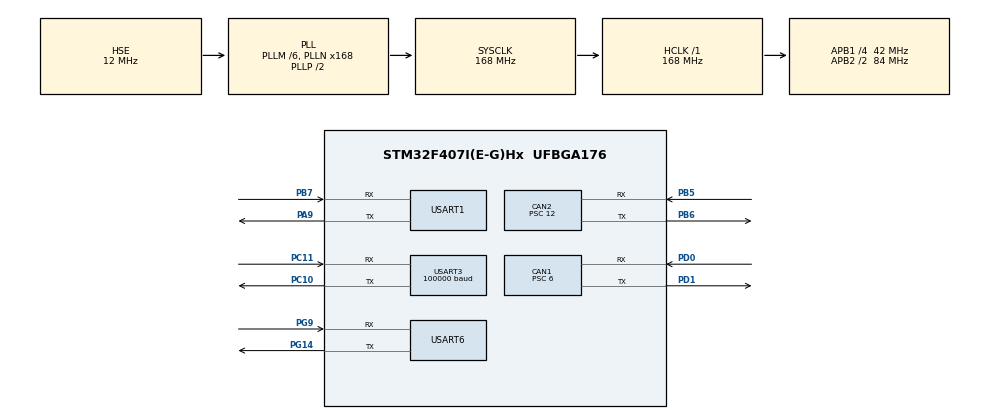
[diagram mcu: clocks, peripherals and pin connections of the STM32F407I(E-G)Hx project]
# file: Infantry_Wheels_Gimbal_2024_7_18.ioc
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CAN1.BS1=CAN_BS1_4TQ
CAN1.BS2=CAN_BS2_2TQ
CAN1.CalculateBaudRate=1000000
CAN1.CalculateTimeBit=1000
CAN1.CalculateTimeQuantum=142.85714285714286
CAN1.Prescaler=6
CAN2.BS1=CAN_BS1_4TQ
CAN2.BS2=CAN_BS2_2TQ
CAN2.CalculateBaudRate=500000
CAN2.CalculateTimeBit=2000
CAN2.CalculateTimeQuantum=285.7142857142857
CAN2.Prescaler=12
Dma.Request0=USART1_RX
Dma.Request1=USART1_TX
Dma.Request2=USART6_RX
Dma.Request3=USART6_TX
Dma.USART1_RX.0.Direction=DMA_PERIPH_TO_MEMORY
Dma.USART1_RX.0.FIFOMode=DMA_FIFOMODE_DISABLE
Dma.USART1_RX.0.Instance=DMA2_Stream2
Dma.USART1_RX.0.MemDataAlignment=DMA_MDATAALIGN_BYTE
Dma.USART1_RX.0.MemInc=DMA_MINC_ENABLE
Dma.USART1_RX.0.Mode=DMA_NORMAL
Dma.USART1_RX.0.PeriphDataAlignment=DMA_PDATAALIGN_BYTE
Dma.USART1_RX.0.PeriphInc=DMA_PINC_DISABLE
Dma.USART1_RX.0.Priority=DMA_PRIORITY_LOW
Dma.USART1_TX.1.Direction=DMA_MEMORY_TO_PERIPH
Dma.USART1_TX.1.FIFOMode=DMA_FIFOMODE_DISABLE
Dma.USART1_TX.1.Instance=DMA2_Stream7
Dma.USART1_TX.1.MemDataAlignment=DMA_MDATAALIGN_BYTE
Dma.USART1_TX.1.MemInc=DMA_MINC_ENABLE
Dma.USART1_TX.1.Mode=DMA_NORMAL
Dma.USART1_TX.1.PeriphDataAlignment=DMA_PDATAALIGN_BYTE
Dma.USART1_TX.1.PeriphInc=DMA_PINC_DISABLE
Dma.USART1_TX.1.Priority=DMA_PRIORITY_LOW
Dma.USART6_RX.2.Direction=DMA_PERIPH_TO_MEMORY
Dma.USART6_RX.2.FIFOMode=DMA_FIFOMODE_DISABLE
Dma.USART6_RX.2.Instance=DMA2_Stream1
Dma.USART6_RX.2.MemDataAlignment=DMA_MDATAALIGN_BYTE
Dma.USART6_RX.2.MemInc=DMA_MINC_ENABLE
Dma.USART6_RX.2.Mode=DMA_NORMAL
Dma.USART6_RX.2.PeriphDataAlignment=DMA_PDATAALIGN_BYTE
Dma.USART6_RX.2.PeriphInc=DMA_PINC_DISABLE
Dma.USART6_RX.2.Priority=DMA_PRIORITY_LOW
Dma.USART6_TX.3.Direction=DMA_MEMORY_TO_PERIPH
Dma.USART6_TX.3.FIFOMode=DMA_FIFOMODE_DISABLE
Dma.USART6_TX.3.Instance=DMA2_Stream6
Dma.USART6_TX.3.MemDataAlignment=DMA_MDATAALIGN_BYTE
Dma.USART6_TX.3.MemInc=DMA_MINC_ENABLE
Dma.USART6_TX.3.Mode=DMA_NORMAL
Dma.USART6_TX.3.PeriphDataAlignment=DMA_PDATAALIGN_BYTE
Dma.USART6_TX.3.PeriphInc=DMA_PINC_DISABLE
Dma.USART6_TX.3.Priority=DMA_PRIORITY_LOW
Mcu.Family=STM32F4
Mcu.Name=STM32F407I(E-G)Hx
Mcu.Package=UFBGA176
NVIC.CAN1_RX0_IRQn=true\:0\:0\:false\:false\:true\:true\:true\:true
NVIC.CAN1_RX1_IRQn=true\:0\:0\:false\:false\:true\:true\:true\:true
NVIC.CAN2_RX0_IRQn=true\:0\:0\:false\:false\:true\:true\:true\:true
NVIC.CAN2_RX1_IRQn=true\:0\:0\:false\:false\:true\:true\:true\:true
NVIC.DMA2_Stream1_IRQn=true\:0\:0\:false\:false\:true\:false\:true\:true
NVIC.DMA2_Stream2_IRQn=true\:0\:0\:false\:false\:true\:false\:true\:true
NVIC.DMA2_Stream6_IRQn=true\:0\:0\:false\:false\:true\:false\:true\:true
NVIC.DMA2_Stream7_IRQn=true\:0\:0\:false\:false\:true\:false\:true\:true
NVIC.PriorityGroup=NVIC_PRIORITYGROUP_4
NVIC.TIM5_IRQn=true\:0\:0\:false\:false\:true\:true\:true\:true
NVIC.TIM6_DAC_IRQn=true\:0\:0\:false\:false\:true\:true\:true\:true
NVIC.USART1_IRQn=true\:0\:0\:false\:false\:true\:true\:true\:true
NVIC.USART3_IRQn=true\:0\:0\:false\:false\:true\:true\:true\:true
NVIC.USART6_IRQn=true\:0\:0\:false\:false\:true\:true\:true\:true
PA13.Mode=Serial_Wire
PA13.Signal=SYS_JTMS-SWDIO
PA14.Mode=Serial_Wire
PA14.Signal=SYS_JTCK-SWCLK
PA9.Mode=Asynchronous
PA9.Signal=USART1_TX
PB5.Mode=CAN_Activate
PB5.Signal=CAN2_RX
PB6.Mode=CAN_Activate
PB6.Signal=CAN2_TX
PB7.Mode=Asynchronous
PB7.Signal=USART1_RX
PC10.Mode=Asynchronous
PC10.Signal=USART3_TX
PC11.Mode=Asynchronous
PC11.Signal=USART3_RX
PD0.Mode=CAN_Activate
PD0.Signal=CAN1_RX
PD1.Mode=CAN_Activate
PD1.Signal=CAN1_TX
PG14.Mode=Asynchronous
PG14.Signal=USART6_TX
PG9.Mode=Asynchronous
PG9.Signal=USART6_RX
PH0-OSC_IN.Mode=HSE-External-Oscillator
PH0-OSC_IN.Signal=RCC_OSC_IN
PH1-OSC_OUT.Mode=HSE-External-Oscillator
PH1-OSC_OUT.Signal=RCC_OSC_OUT
ProjectManager.HeapSize=0x200
ProjectManager.StackSize=0x400
ProjectManager.TargetToolchain=MDK-ARM V5.32
RCC.48MHZClocksFreq_Value=84000000
RCC.AHBFreq_Value=168000000
RCC.APB1CLKDivider=RCC_HCLK_DIV4
RCC.APB1Freq_Value=42000000
RCC.APB1TimFreq_Value=84000000
RCC.APB2CLKDivider=RCC_HCLK_DIV2
RCC.APB2Freq_Value=84000000
RCC.APB2TimFreq_Value=168000000
RCC.CortexFreq_Value=168000000
RCC.HCLKFreq_Value=168000000
RCC.HSE_VALUE=12000000
RCC.HSI_VALUE=16000000
RCC.LSE_VALUE=32768
RCC.PLLM=6
RCC.PLLN=168
RCC.PLLSourceVirtual=RCC_PLLSOURCE_HSE
RCC.SYSCLKFreq_VALUE=168000000
RCC.SYSCLKSource=RCC_SYSCLKSOURCE_PLLCLK
RCC.VCOOutputFreq_Value=336000000
TIM5.AutoReloadPreload=TIM_AUTORELOAD_PRELOAD_ENABLE
TIM5.Period=1000-1
TIM5.Prescaler=84-1
TIM6.AutoReloadPreload=TIM_AUTORELOAD_PRELOAD_ENABLE
TIM6.Period=1000-1
TIM6.Prescaler=84-1
USART1.VirtualMode=VM_ASYNC
USART3.BaudRate=100000
USART3.Parity=PARITY_EVEN
USART3.VirtualMode=VM_ASYNC
USART3.WordLength=WORDLENGTH_9B
USART6.VirtualMode=VM_ASYNC
VP_TIM5_VS_ClockSourceINT.Mode=Internal
VP_TIM6_VS_ClockSourceINT.Mode=Enable_Timer
board=custom

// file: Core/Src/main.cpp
/* USER CODE BEGIN Header */
/**
  ******************************************************************************
  * @file           : main.c
  * @brief          : Main program body
  ******************************************************************************
  * @attention
  *
  * Copyright (c) 2024 STMicroelectronics.
  * All rights reserved.
  *
  * This software is licensed under terms that can be found in the LICENSE file
  * in the root directory of this software component.
  * If no LICENSE file comes with this software, it is provided AS-IS.
  *
  ******************************************************************************
  */
/* USER CODE END Header */
#include "main.h"
#include "can.h"
#include "dma.h"
#include "tim.h"
#include "usart.h"
#include "gpio.h"

/* USER CODE BEGIN Includes */
#include "Total_stack.h"
/* USER CODE END Includes */

void SystemClock_Config(void);

int main(void)
{

  /* MCU Configuration--------------------------------------------------------*/

  /* Reset of all peripherals, Initializes the Flash interface and the Systick. */
  HAL_Init();

  /* Configure the system clock */
  SystemClock_Config();

  /* Initialize all configured peripherals */
  MX_GPIO_Init();
  MX_DMA_Init();
  MX_CAN1_Init();
  MX_CAN2_Init();
  MX_USART1_UART_Init();
  MX_USART3_UART_Init();
  MX_USART6_UART_Init();
  MX_TIM5_Init();
  MX_TIM6_Init();
  /* USER CODE BEGIN 2 */
	Total_tasks_Init();//?????????????
	HAL_TIM_Base_Start_IT(&htim6);//?????????
	HAL_TIM_Base_Start_IT(&htim5);//????
  /* USER CODE END 2 */

  /* Infinite loop */
  while (1)
  {

    /* USER CODE BEGIN 3 */
		Total_tasks_Run();
  }
  /* USER CODE END 3 */
}

void SystemClock_Config(void)
{
  RCC_OscInitTypeDef RCC_OscInitStruct = {0};
  RCC_ClkInitTypeDef RCC_ClkInitStruct = {0};

  /** Configure the main internal regulator output voltage
  */
  __HAL_RCC_PWR_CLK_ENABLE();
  __HAL_PWR_VOLTAGESCALING_CONFIG(PWR_REGULATOR_VOLTAGE_SCALE1);

  /** Initializes the RCC Oscillators according to the specified parameters
  * in the RCC_OscInitTypeDef structure.
  */
  RCC_OscInitStruct.OscillatorType = RCC_OSCILLATORTYPE_HSE;
  RCC_OscInitStruct.HSEState = RCC_HSE_ON;
  RCC_OscInitStruct.PLL.PLLState = RCC_PLL_ON;
  RCC_OscInitStruct.PLL.PLLSource = RCC_PLLSOURCE_HSE;
  RCC_OscInitStruct.PLL.PLLM = 6;
  RCC_OscInitStruct.PLL.PLLN = 168;
  RCC_OscInitStruct.PLL.PLLP = RCC_PLLP_DIV2;
  RCC_OscInitStruct.PLL.PLLQ = 4;
  if (HAL_RCC_OscConfig(&RCC_OscInitStruct) != HAL_OK)
  {
    Error_Handler();
  }

  /** Initializes the CPU, AHB and APB buses clocks
  */
  RCC_ClkInitStruct.ClockType = RCC_CLOCKTYPE_HCLK|RCC_CLOCKTYPE_SYSCLK
                              |RCC_CLOCKTYPE_PCLK1|RCC_CLOCKTYPE_PCLK2;
  RCC_ClkInitStruct.SYSCLKSource = RCC_SYSCLKSOURCE_PLLCLK;
  RCC_ClkInitStruct.AHBCLKDivider = RCC_SYSCLK_DIV1;
  RCC_ClkInitStruct.APB1CLKDivider = RCC_HCLK_DIV4;
  RCC_ClkInitStruct.APB2CLKDivider = RCC_HCLK_DIV2;

  if (HAL_RCC_ClockConfig(&RCC_ClkInitStruct, FLASH_LATENCY_5) != HAL_OK)
  {
    Error_Handler();
  }
}

static void MX_CAN1_Init(void)
{

  hcan1.Instance = CAN1;
  hcan1.Init.Prescaler = 6;
  hcan1.Init.Mode = CAN_MODE_NORMAL;
  hcan1.Init.SyncJumpWidth = CAN_SJW_1TQ;
  hcan1.Init.TimeSeg1 = CAN_BS1_4TQ;
  hcan1.Init.TimeSeg2 = CAN_BS2_2TQ;
  hcan1.Init.TimeTriggeredMode = DISABLE;
  hcan1.Init.AutoBusOff = DISABLE;
  hcan1.Init.AutoWakeUp = DISABLE;
  hcan1.Init.AutoRetransmission = DISABLE;
  hcan1.Init.ReceiveFifoLocked = DISABLE;
  hcan1.Init.TransmitFifoPriority = DISABLE;
  if (HAL_CAN_Init(&hcan1) != HAL_OK)
  {
    Error_Handler();
  }

}

static void MX_CAN2_Init(void)
{

  hcan2.Instance = CAN2;
  hcan2.Init.Prescaler = 12;
  hcan2.Init.Mode = CAN_MODE_NORMAL;
  hcan2.Init.SyncJumpWidth = CAN_SJW_1TQ;
  hcan2.Init.TimeSeg1 = CAN_BS1_4TQ;
  hcan2.Init.TimeSeg2 = CAN_BS2_2TQ;
  hcan2.Init.TimeTriggeredMode = DISABLE;
  hcan2.Init.AutoBusOff = DISABLE;
  hcan2.Init.AutoWakeUp = DISABLE;
  hcan2.Init.AutoRetransmission = DISABLE;
  hcan2.Init.ReceiveFifoLocked = DISABLE;
  hcan2.Init.TransmitFifoPriority = DISABLE;
  if (HAL_CAN_Init(&hcan2) != HAL_OK)
  {
    Error_Handler();
  }

}

static void MX_TIM5_Init(void)
{

  TIM_ClockConfigTypeDef sClockSourceConfig = {0};
  TIM_MasterConfigTypeDef sMasterConfig = {0};

  htim5.Instance = TIM5;
  htim5.Init.Prescaler = 84-1;
  htim5.Init.CounterMode = TIM_COUNTERMODE_UP;
  htim5.Init.Period = 1000-1;
  htim5.Init.ClockDivision = TIM_CLOCKDIVISION_DIV1;
  htim5.Init.AutoReloadPreload = TIM_AUTORELOAD_PRELOAD_ENABLE;
  if (HAL_TIM_Base_Init(&htim5) != HAL_OK)
  {
    Error_Handler();
  }
  sClockSourceConfig.ClockSource = TIM_CLOCKSOURCE_INTERNAL;
  if (HAL_TIM_ConfigClockSource(&htim5, &sClockSourceConfig) != HAL_OK)
  {
    Error_Handler();
  }
  sMasterConfig.MasterOutputTrigger = TIM_TRGO_RESET;
  sMasterConfig.MasterSlaveMode = TIM_MASTERSLAVEMODE_DISABLE;
  if (HAL_TIMEx_MasterConfigSynchronization(&htim5, &sMasterConfig) != HAL_OK)
  {
    Error_Handler();
  }

}

static void MX_TIM6_Init(void)
{

  TIM_MasterConfigTypeDef sMasterConfig = {0};

  htim6.Instance = TIM6;
  htim6.Init.Prescaler = 84-1;
  htim6.Init.CounterMode = TIM_COUNTERMODE_UP;
  htim6.Init.Period = 1000-1;
  htim6.Init.AutoReloadPreload = TIM_AUTORELOAD_PRELOAD_ENABLE;
  if (HAL_TIM_Base_Init(&htim6) != HAL_OK)
  {
    Error_Handler();
  }
  sMasterConfig.MasterOutputTrigger = TIM_TRGO_RESET;
  sMasterConfig.MasterSlaveMode = TIM_MASTERSLAVEMODE_DISABLE;
  if (HAL_TIMEx_MasterConfigSynchronization(&htim6, &sMasterConfig) != HAL_OK)
  {
    Error_Handler();
  }

}

static void MX_USART1_UART_Init(void)
{

  huart1.Instance = USART1;
  huart1.Init.BaudRate = 115200;
  huart1.Init.WordLength = UART_WORDLENGTH_8B;
  huart1.Init.StopBits = UART_STOPBITS_1;
  huart1.Init.Parity = UART_PARITY_NONE;
  huart1.Init.Mode = UART_MODE_TX_RX;
  huart1.Init.HwFlowCtl = UART_HWCONTROL_NONE;
  huart1.Init.OverSampling = UART_OVERSAMPLING_16;
  if (HAL_UART_Init(&huart1) != HAL_OK)
  {
    Error_Handler();
  }

}

static void MX_USART3_UART_Init(void)
{

  huart3.Instance = USART3;
  huart3.Init.BaudRate = 100000;
  huart3.Init.WordLength = UART_WORDLENGTH_9B;
  huart3.Init.StopBits = UART_STOPBITS_1;
  huart3.Init.Parity = UART_PARITY_EVEN;
  huart3.Init.Mode = UART_MODE_TX_RX;
  huart3.Init.HwFlowCtl = UART_HWCONTROL_NONE;
  huart3.Init.OverSampling = UART_OVERSAMPLING_16;
  if (HAL_UART_Init(&huart3) != HAL_OK)
  {
    Error_Handler();
  }

}

static void MX_USART6_UART_Init(void)
{

  huart6.Instance = USART6;
  huart6.Init.BaudRate = 115200;
  huart6.Init.WordLength = UART_WORDLENGTH_8B;
  huart6.Init.StopBits = UART_STOPBITS_1;
  huart6.Init.Parity = UART_PARITY_NONE;
  huart6.Init.Mode = UART_MODE_TX_RX;
  huart6.Init.HwFlowCtl = UART_HWCONTROL_NONE;
  huart6.Init.OverSampling = UART_OVERSAMPLING_16;
  if (HAL_UART_Init(&huart6) != HAL_OK)
  {
    Error_Handler();
  }

}

static void MX_DMA_Init(void)
{

  /* DMA controller clock enable */
  __HAL_RCC_DMA2_CLK_ENABLE();

  /* DMA interrupt init */
  /* DMA2_Stream1_IRQn interrupt configuration */
  HAL_NVIC_SetPriority(DMA2_Stream1_IRQn, 0, 0);
  HAL_NVIC_EnableIRQ(DMA2_Stream1_IRQn);
  /* DMA2_Stream2_IRQn interrupt configuration */
  HAL_NVIC_SetPriority(DMA2_Stream2_IRQn, 0, 0);
  HAL_NVIC_EnableIRQ(DMA2_Stream2_IRQn);
  /* DMA2_Stream6_IRQn interrupt configuration */
  HAL_NVIC_SetPriority(DMA2_Stream6_IRQn, 0, 0);
  HAL_NVIC_EnableIRQ(DMA2_Stream6_IRQn);
  /* DMA2_Stream7_IRQn interrupt configuration */
  HAL_NVIC_SetPriority(DMA2_Stream7_IRQn, 0, 0);
  HAL_NVIC_EnableIRQ(DMA2_Stream7_IRQn);

}

static void MX_GPIO_Init(void)
{

  /* GPIO Ports Clock Enable */
  __HAL_RCC_GPIOB_CLK_ENABLE();
  __HAL_RCC_GPIOG_CLK_ENABLE();
  __HAL_RCC_GPIOA_CLK_ENABLE();
  __HAL_RCC_GPIOC_CLK_ENABLE();
  __HAL_RCC_GPIOH_CLK_ENABLE();

}

void Error_Handler(void)
{
  __disable_irq();
  while (1)
  {
  }
}
